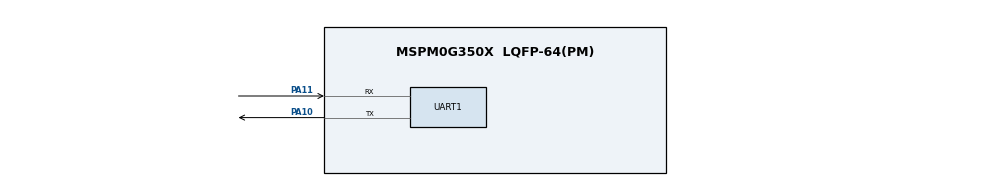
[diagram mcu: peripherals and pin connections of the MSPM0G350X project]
/**
 * @cliArgs --device "MSPM0G350X" --part "Default" --package "LQFP-64(PM)" --product "mspm0_sdk@2.04.00.06"
 * @versions {"tool":"1.22.0+3893"}
 */

/**
 * Import the modules used in this configuration.
 */
const ADC12         = scripting.addModule("/ti/driverlib/ADC12", {}, false);
const ADC121        = ADC12.addInstance();
const GPIO          = scripting.addModule("/ti/driverlib/GPIO", {}, false);
const GPIO1         = GPIO.addInstance();
const GPIO2         = GPIO.addInstance();
const GPIO3         = GPIO.addInstance();
const GPIO4         = GPIO.addInstance();
const SYSCTL        = scripting.addModule("/ti/driverlib/SYSCTL");
const TIMER         = scripting.addModule("/ti/driverlib/TIMER", {}, false);
const TIMER1        = TIMER.addInstance();
const TIMER2        = TIMER.addInstance();
const UART          = scripting.addModule("/ti/driverlib/UART", {}, false);
const UART1         = UART.addInstance();
const ProjectConfig = scripting.addModule("/ti/project_config/ProjectConfig");

/**
 * Write custom configuration values to the imported modules.
 */
const divider9       = system.clockTree["UDIV"];
divider9.divideValue = 2;

const multiplier2         = system.clockTree["PLL_QDIV"];
multiplier2.multiplyValue = 4;

const mux4       = system.clockTree["EXHFMUX"];
mux4.inputSelect = "EXHFMUX_XTAL";

const mux8       = system.clockTree["HSCLKMUX"];
mux8.inputSelect = "HSCLKMUX_SYSPLL0";

const mux12       = system.clockTree["SYSPLLMUX"];
mux12.inputSelect = "zSYSPLLMUX_HFCLK";

const pinFunction4        = system.clockTree["HFXT"];
pinFunction4.HFCLKMonitor = true;
pinFunction4.enable       = true;
pinFunction4.inputFreq    = 40;
pinFunction4.HFXTStartup  = 100;

ADC121.$name                             = "ADC12_0";
ADC121.repeatMode                        = true;
ADC121.powerDownMode                     = "DL_ADC12_POWER_DOWN_MODE_MANUAL";
ADC121.configureDMA                      = true;
ADC121.enabledInterrupts                 = ["DL_ADC12_INTERRUPT_DMA_DONE"];
ADC121.sampleTime0                       = "1us";
ADC121.subChanID                         = 1;
ADC121.trigSrc                           = "DL_ADC12_TRIG_SRC_EVENT";
ADC121.adcMem0trig                       = "DL_ADC12_TRIGGER_MODE_TRIGGER_NEXT";
ADC121.sampCnt                           = 1;
ADC121.enabledDMATriggers                = ["DL_ADC12_DMA_MEM0_RESULT_LOADED"];
ADC121.peripheral.adcPin0.$assign        = "PA27";
ADC121.adcPin0Config.$name               = "ti_driverlib_gpio_GPIOPinGeneric0";
ADC121.DMA_CHANNEL.$name                 = "DMA_CH0";
ADC121.DMA_CHANNEL.addressMode           = "f2b";
ADC121.DMA_CHANNEL.configureTransferSize = true;
ADC121.DMA_CHANNEL.transferMode          = "FULL_CH_REPEAT_SINGLE";
ADC121.DMA_CHANNEL.srcLength             = "HALF_WORD";
ADC121.DMA_CHANNEL.dstLength             = "HALF_WORD";
ADC121.DMA_CHANNEL.transferSize          = 1024;

const Board = scripting.addModule("/ti/driverlib/Board", {}, false);

GPIO1.$name                          = "GPIO_OLED";
GPIO1.associatedPins.create(2);
GPIO1.associatedPins[0].$name        = "PIN_SCL";
GPIO1.associatedPins[0].assignedPort = "PORTA";
GPIO1.associatedPins[0].assignedPin  = "12";
GPIO1.associatedPins[1].$name        = "PIN_SDA";
GPIO1.associatedPins[1].assignedPort = "PORTA";
GPIO1.associatedPins[1].assignedPin  = "13";

GPIO2.$name                          = "GPIO_GRP_0";
GPIO2.associatedPins[0].$name        = "PIN_0";
GPIO2.associatedPins[0].assignedPort = "PORTA";

GPIO3.$name                              = "GPIO_SWITCHES";
GPIO3.associatedPins[0].$name            = "USER_SWITCH_1";
GPIO3.associatedPins[0].direction        = "INPUT";
GPIO3.associatedPins[0].assignedPort     = "PORTB";
GPIO3.associatedPins[0].assignedPin      = "21";
GPIO3.associatedPins[0].internalResistor = "PULL_UP";
GPIO3.associatedPins[0].interruptEn      = true;
GPIO3.associatedPins[0].polarity         = "RISE_FALL";

GPIO4.$name                          = "GPIO_LEDS";
GPIO4.associatedPins[0].$name        = "USER_LED_1";
GPIO4.associatedPins[0].initialValue = "SET";
GPIO4.associatedPins[0].assignedPort = "PORTA";
GPIO4.associatedPins[0].assignedPin  = "0";

SYSCTL.forceDefaultClkConfig = true;
SYSCTL.validateClkStatus     = true;

TIMER1.$name                       = "TIMER_0";
TIMER1.timerPeriod                 = "1us";
TIMER1.timerStartTimer             = true;
TIMER1.event1PublisherChannel      = 1;
TIMER1.event1ControllerInterruptEn = ["ZERO_EVENT"];
TIMER1.timerMode                   = "PERIODIC";

TIMER2.$name                       = "TIMER_1";
TIMER2.timerMode                   = "PERIODIC";
TIMER2.timerStartTimer             = true;
TIMER2.timerPeriod                 = "20us";
TIMER2.event1PublisherChannel      = 2;
TIMER2.event1ControllerInterruptEn = ["ZERO_EVENT"];

UART1.$name                    = "UART_0";
UART1.uartClkSrc               = "LFCLK";
UART1.ovsRate                  = "3";
UART1.peripheral.rxPin.$assign = "PA11";
UART1.peripheral.txPin.$assign = "PA10";
UART1.txPinConfig.$name        = "ti_driverlib_gpio_GPIOPinGeneric1";
UART1.rxPinConfig.$name        = "ti_driverlib_gpio_GPIOPinGeneric2";

ProjectConfig.genLibCMSIS   = true;
ProjectConfig.genLibDrivers = true;

/**
 * Pinmux solution for unlocked pins/peripherals. This ensures that minor changes to the automatic solver in a future
 * version of the tool will not impact the pinmux you originally saw.  These lines can be completely deleted in order to
 * re-solve from scratch.
 */
pinFunction4.peripheral.$suggestSolution           = "SYSCTL";
pinFunction4.peripheral.hfxInPin.$suggestSolution  = "PA5";
pinFunction4.peripheral.hfxOutPin.$suggestSolution = "PA6";
ADC121.peripheral.$suggestSolution                 = "ADC0";
ADC121.DMA_CHANNEL.peripheral.$suggestSolution     = "DMA_CH0";
Board.peripheral.$suggestSolution                  = "DEBUGSS";
Board.peripheral.swclkPin.$suggestSolution         = "PA20";
Board.peripheral.swdioPin.$suggestSolution         = "PA19";
GPIO1.associatedPins[0].pin.$suggestSolution       = "PA12";
GPIO1.associatedPins[1].pin.$suggestSolution       = "PA13";
GPIO2.associatedPins[0].pin.$suggestSolution       = "PA14";
GPIO3.associatedPins[0].pin.$suggestSolution       = "PB21";
GPIO4.associatedPins[0].pin.$suggestSolution       = "PA0";
SYSCTL.peripheral.$suggestSolution                 = "SYSCTL";
TIMER1.peripheral.$suggestSolution                 = "TIMA1";
TIMER2.peripheral.$suggestSolution                 = "TIMA0";
UART1.peripheral.$suggestSolution                  = "UART0";
